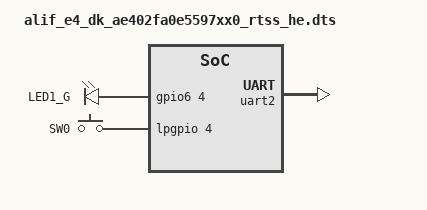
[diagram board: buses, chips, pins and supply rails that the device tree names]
/* Copyright (c) 2025 Alif Semiconductor
 *
 * SPDX-License-Identifier: Apache-2.0
 */

/dts-v1/;

#include <alif/ensemble/e4/ae402fa0e5597xx0.dtsi>
#include <alif/ensemble/common/ensemble_rtss_he.dtsi>
#include "../common/ensemble-e4-e6-e8-pinctrl.dtsi"

/ {
	compatible = "arm,alif-e4-dk-ae402fa0e5597xx0-rtss-he";
	#address-cells = <1>;
	#size-cells = <1>;

	chosen {
		zephyr,flash = &mram_storage;
		zephyr,code-partition = &slot0_partition;
		zephyr,sram = &dtcm;
		zephyr,console = &uart2;
		zephyr,shell-uart = &uart2;
		zephyr,uart-mcumgr = &uart2;
	};

	aliases {
		led0 = &aled0;
		sw0 = &button0;
		watchdog0 = &wdog0;
	};

	leds {
		compatible = "gpio-leds";

		aled0: led_0 {
			gpios = <&gpio6 4 0>;
			label = "LED1_G";
		};
	};
	buttons {
		compatible = "gpio-keys";

		button0: button_0 {
			gpios = < &lpgpio 4 0 >;
			label = "SW0";
		};
	};
};

&lpgpio {
	status = "okay";
};

&gpio6 {
	status = "okay";
};

&uart2 {
	status = "okay";
};

